# R7FA0E107 register map
Vendor: Renesas Electronics Corporation; Series: RA0; File version: 1.20.00
CPU: CM23 r1p0, little endian, no MPU, no FPU, VTOR, 2 interrupt priority bits, 64 interrupts
Registers are 16-bit, read-write, reset 0x0 unless marked. A register's access mark holds for its fields unless they carry their own. Offsets are from the block's base; [hi:lo] are bit positions; {n}, {i} and the like mark numbered series; 'fields as' and 'values as' point back to an identical list.

## IWDT — Independent Watchdog Timer
Base 0x40044400
0x00 IWDTRR 8-bit reset 0xFF — IWDT Refresh Register
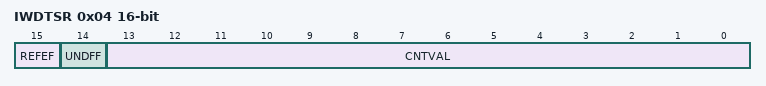
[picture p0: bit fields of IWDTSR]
0x04 IWDTSR — IWDT Status Register
  [15] REFEF — Refresh Error Flag
    0=No refresh error occurred; 1=Refresh error occurred
  [14] UNDFF — Underflow Flag
    0=No underflow occurred; 1=Underflow occurred
  [13:0] CNTVAL ro — Down-counter Value

## MSTP — Module Stop Control
Base 0x40047000
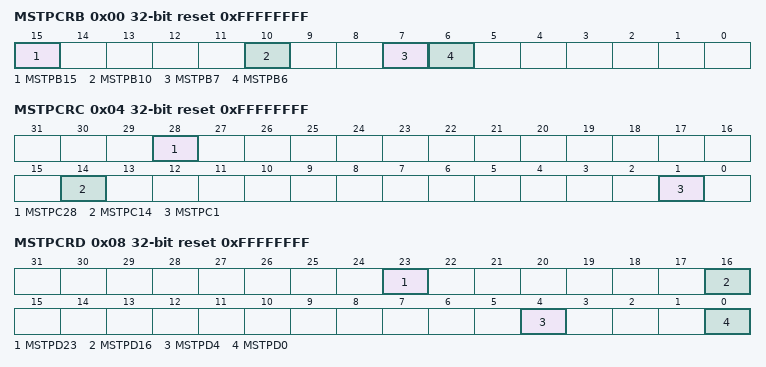
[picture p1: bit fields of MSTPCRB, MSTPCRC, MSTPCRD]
0x00 MSTPCRB 32-bit reset 0xFFFFFFFF — Module Stop Control Register B
  [all] fields
    0=Cancel the module-stop state; 1=Enter the module-stop state
  [15] MSTPB15 — Serial Interface UARTA Module Stop
  [10] MSTPB10 — I2C Bus Interface Module Stop
  [7] MSTPB7 — Serial Array Unit 1 Module Stop
  [6] MSTPB6 — Serial Array Unit 0 Module Stop
0x04 MSTPCRC 32-bit reset 0xFFFFFFFF — Module Stop Control Register C
  [all] fields
    values as the fields of MSTPCRB
  [28] MSTPC28 — True Random Number Generator Module Stop
  [14] MSTPC14 — Event Link Controller Module Stop
  [1] MSTPC1 — Cyclic Redundancy Check Calculator Module Stop
0x08 MSTPCRD 32-bit reset 0xFFFFFFFF — Module Stop Control Register D
  [all] fields
    values as the fields of MSTPCRB
  [23] MSTPD23 — Realtime Clock Module Stop
  [16] MSTPD16 — A/D Converter Module Stop
  [4] MSTPD4 — 32-bit Interval Timer Module Stop
  [0] MSTPD0 — Timer Array Unit 0 Module Stop

## CRC — CRC Calculator
Base 0x40074000
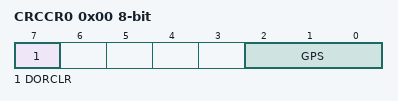
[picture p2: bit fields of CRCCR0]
0x00 CRCCR0 8-bit — CRC Control Register 0
  [7] DORCLR wo — CRCDOR/CRCDOR_HA Register Clear
    0=No effect; 1=Clear the CRCDOR/CRCDOR_HA register
  [2:0] GPS — CRC Generating Polynomial Switching
    3=16-bit CRC-CCITT (X16 + X12 + X5 + 1); 4=32-bit CRC-32 (X32 + X26 + X23 + X22 + X16 + X12 + X11 +X10 + X8 + X7 + X5 + X4 + X2 + X + 1); other=Others (No calculation is executed)
0x04 CRCDIR 32-bit — CRC Data Input Register
0x04 CRCDIR_BY 8-bit (alternate view of CRCDIR) — CRC Data Input Register
0x08 CRCDOR 32-bit — CRC Data Output Register
0x08 CRCDOR_HA (alternate view of CRCDOR) — CRC Data Output Register

## PORT0 — Port 0 Control
Base 0x400A0000
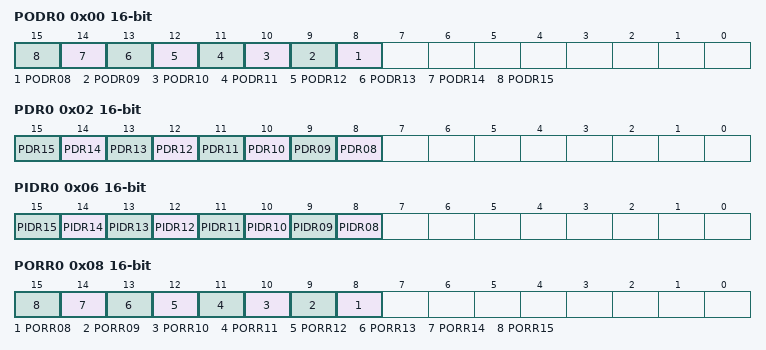
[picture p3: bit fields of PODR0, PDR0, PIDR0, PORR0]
0x00 PODR0 — Port 0 Output Data Register
  [all] fields
    0=Low output; 1=High output
  [n] PODR{n:02} (n=8..15) — P{n:03} Output Data
0x02 PDR0 — Port 0 Direction Register
  [all] fields
    0=Output 0; 1=Output 1
  [n] PDR{n:02} (n=8..15) — P{n:03} Direction
0x06 PIDR0 ro — Port 0 State Register
  [all] fields
    0=Low level; 1=High level
  [n] PIDR{n:02} (n=8..15) — P{n:03} State
0x08 PORR0 wo — Port 0 Output Reset Register
  [all] fields
    0=No effect on output; 1=Low output
  [n] PORR{n:02} (n=8..15) — P{n:03} Output Reset
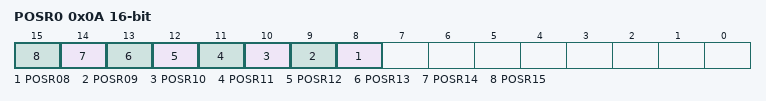
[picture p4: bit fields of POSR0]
0x0A POSR0 wo — Port 0 Output Set Register
  [all] fields
    0=No effect on output; 1=High output
  [n] POSR{n:02} (n=8..15) — P{n:03} Output Set

## PORT1 — Port 1 Control
Base 0x400A0020
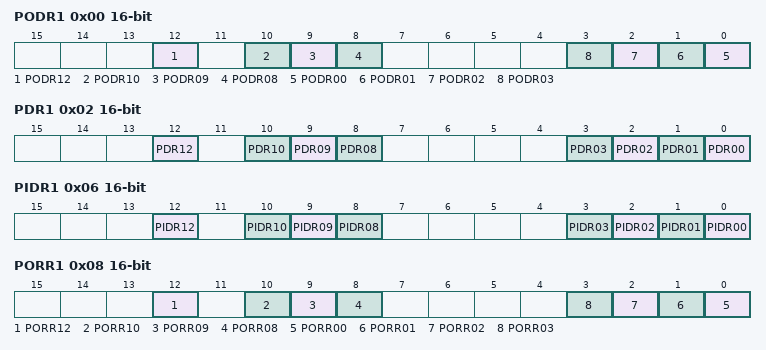
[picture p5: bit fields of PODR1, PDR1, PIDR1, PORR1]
0x00 PODR1 — Port 1 Output Data Register
  [all] fields
    0=Low output; 1=High output
  [12] PODR12 — P112 Output Data
  [10] PODR10 — P110 Output Data
  [9] PODR09 — P109 Output Data
  [8] PODR08 — P108 Output Data
  [n] PODR{n:02} (n=0..3) — P{n+100} Output Data
0x02 PDR1 — Port 1 Direction Register
  [all] fields
    0=Output 0; 1=Output 1
  [12] PDR12 — P112 Direction
  [10] PDR10 — P110 Direction
  [9] PDR09 — P109 Direction
  [8] PDR08 — P108 Direction
  [n] PDR{n:02} (n=0..3) — P{n+100} Direction
0x06 PIDR1 ro (reset mask 0xE8F3) — Port 1 State Register
  [all] fields
    0=Low level; 1=High level
  [12] PIDR12 — P112 State
  [10] PIDR10 — P110 State
  [9] PIDR09 — P109 State
  [8] PIDR08 — P108 State
  [n] PIDR{n:02} (n=0..3) — P{n+100} State
0x08 PORR1 wo — Port 1 Output Reset Register
  [all] fields
    0=No effect on output; 1=Low output
  [12] PORR12 — P112 Output Reset
  [10] PORR10 — P110 Output Reset
  [9] PORR09 — P109 Output Reset
  [8] PORR08 — P108 Output Reset
  [n] PORR{n:02} (n=0..3) — P{n+100} Output Reset
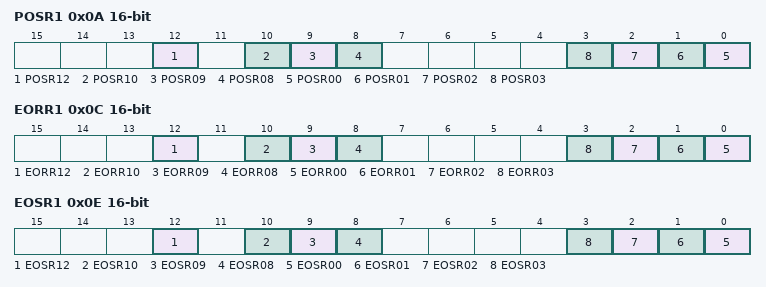
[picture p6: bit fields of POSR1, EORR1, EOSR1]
0x0A POSR1 wo — Port 1 Output Set Register
  [all] fields
    0=No effect on output; 1=High output
  [12] POSR12 — P112 Output Set
  [10] POSR10 — P110 Output Set
  [9] POSR09 — P109 Output Set
  [8] POSR08 — P108 Output Set
  [n] POSR{n:02} (n=0..3) — P{n+100} Output Set
0x0C EORR1 — Port 1 Event Output Reset Register
  [all] fields
    0=No effect on output; 1=Low output
  [12] EORR12 — P112 Event Output Reset
  [10] EORR10 — P110 Event Output Reset
  [9] EORR09 — P109 Event Output Reset
  [8] EORR08 — P108 Event Output Reset
  [n] EORR{n:02} (n=0..3) — P{n+100} Event Output Reset
0x0E EOSR1 — Port 1 Event Output Set Register
  [all] fields
    0=No effect on output; 1=High output
  [12] EOSR12 — P112 Event Output Set
  [10] EOSR10 — P110 Event Output Set
  [9] EOSR09 — P109 Event Output Set
  [8] EOSR08 — P108 Event Output Set
  [n] EOSR{n:02} (n=0..3) — P{n+100} Event Output Set

## Notices in the file
This software is supplied by Renesas Electronics Corporation and is only intended for
use with Renesas products. No other uses are authorized. This software is owned by
Renesas Electronics Corporation and is protected under all applicable laws, including
copyright laws.
THIS SOFTWARE IS PROVIDED "AS IS" AND RENESAS MAKES NO WARRANTIES REGARDING
THIS SOFTWARE, WHETHER EXPRESS, IMPLIED OR STATUTORY, INCLUDING BUT NOT LIMITED TO
WARRANTIES OF MERCHANTABILITY, FITNESS FOR A PARTICULAR PURPOSE AND NON-INFRINGEMENT.
ALL SUCH WARRANTIES ARE EXPRESSLY DISCLAIMED. TO THE MAXIMUM EXTENT PERMITTED NOT
PROHIBITED BY LAW, NEITHER RENESAS ELECTRONICS CORPORATION NOR ANY OF ITS AFFILIATED
COMPANIES SHALL BE LIABLE FOR ANY DIRECT, INDIRECT, SPECIAL, INCIDENTAL OR CONSEQUENTIAL
DAMAGES FOR ANY REASON RELATED TO THIS SOFTWARE, EVEN IF RENESAS OR ITS AFFILIATES HAVE
BEEN ADVISED OF THE POSSIBILITY OF SUCH DAMAGES.
Renesas reserves the right, without notice, to make changes to this software and to
discontinue the availability of this software. By using this software, you agree to
the additional terms and conditions found by accessing the following link:
http://www.renesas.com/disclaimer
